# AC7840x register map
Vendor: AutoChips; Series: AC78; File version: 1.0
CPU: CM4 r0p1, little endian, MPU, FPU, VTOR, 4 interrupt priority bits
Registers are 32-bit, read-write, reset 0x0 unless marked. A register's access mark holds for its fields unless they carry their own. Offsets are from the block's base; [hi:lo] are bit positions; {n}, {i} and the like mark numbered series; 'fields as' and 'values as' point back to an identical list.

## GPIOA — General Purpose Input/Output
Base 0x40085000
Same registers: GPIOB 0x40085040, GPIOC 0x40085080, GPIOD 0x400850C0, GPIOE 0x40085100
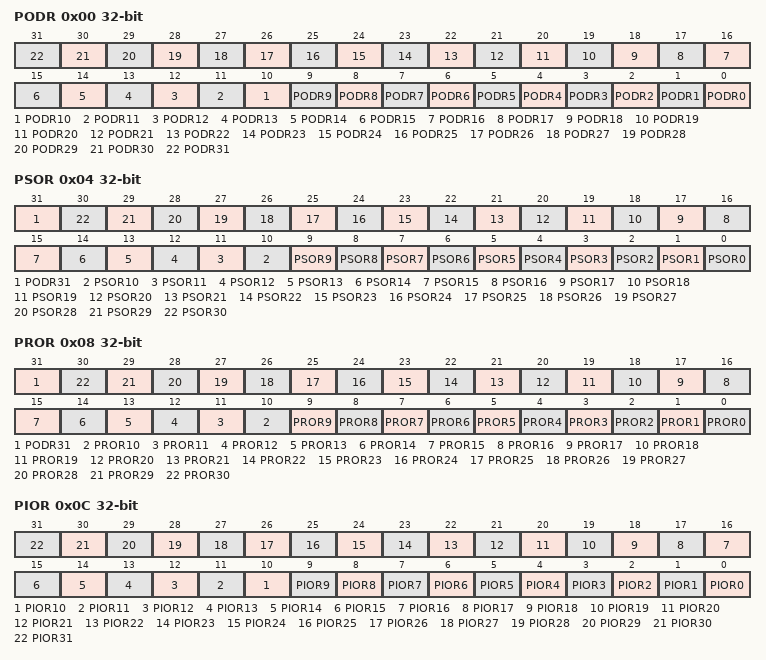
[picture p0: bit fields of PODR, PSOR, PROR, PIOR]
0x00 PODR — PORT Output Data Register
  [n] PODR{n} (n=0..31) — Port output data, bit {n}
0x04 PSOR — PORT Set Output Register
  [31] PODR31 — Port Set Output data, bit 31
  [n] PSOR{n} (n=0..30) — Port Set Output data, bit {n}
0x08 PROR — PORT Reset Output Register
  [31] PODR31 — Port Reset Output data, bit 31
  [n] PROR{n} (n=0..30) — Port Reset Output data, bit {n}
0x0C PIOR — PORT Invert Output Register
  [n] PIOR{n} (n=0..31) — Port Invert Output data, bit {n}
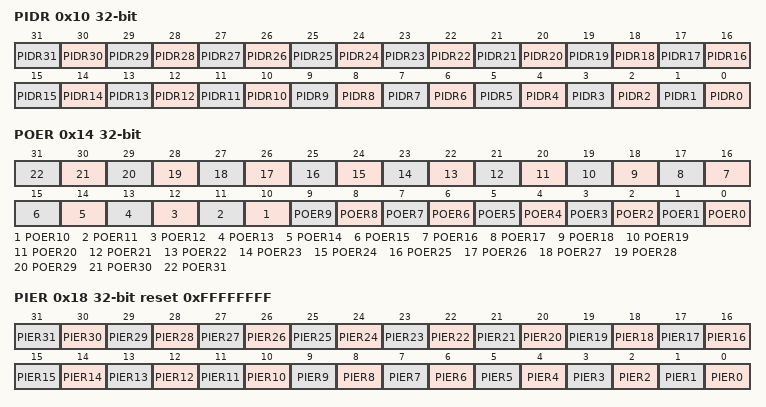
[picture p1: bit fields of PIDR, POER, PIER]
0x10 PIDR — PORT Input Data Register
  [n] PIDR{n} (n=0..31) — Port Input data, bit {n}
0x14 POER — PORT Output Enable Register
  [n] POER{n} (n=0..31) — Port Output Enable, bit {n}
0x18 PIER reset 0xFFFFFFFF — PORT Input Enable Register
  [n] PIER{n} (n=0..31) — Port Input Enable, bit {n}

## ANA — Analog Control Registers
Base 0x40008800
0x50 ACMPDAC_CFG reset 0x1000000 — ACMPDAC Configuration Register
  [16] RG_MCU_ACMPDAC_LP_EN — LP mode
    1=enable; 0=disable
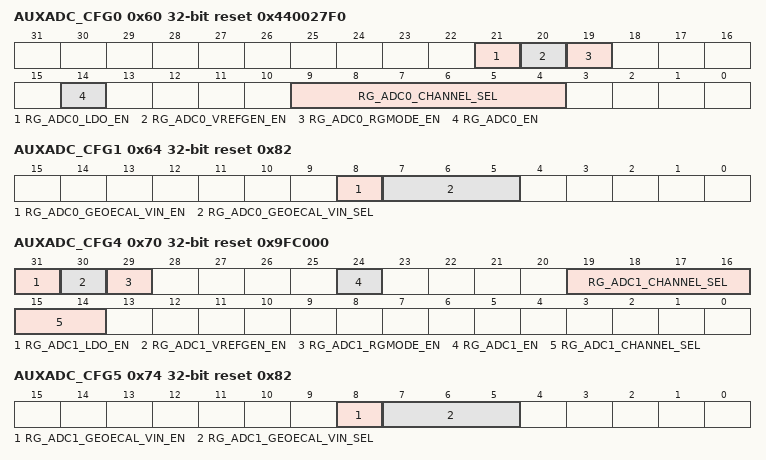
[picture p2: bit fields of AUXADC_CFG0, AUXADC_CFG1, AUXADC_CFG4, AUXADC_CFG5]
0x60 AUXADC_CFG0 reset 0x440027F0 — AUXADC Configuration Register0
  [21] RG_ADC0_LDO_EN — ADC0 LDO enable
    0=disable; 1=enable
  [20] RG_ADC0_VREFGEN_EN — ADC0 VREFGEN enable
    0=disable; 1=enable
  [19] RG_ADC0_RGMODE_EN — Registor debug mode enable
    0=normal mode, enable and channel_sel are controled by DA signal; 1=debug mode, enable and channel_sel are controled by RG signal
  [14] RG_ADC0_EN — ADC Enable
    0=disable; 1=enable
  [9:4] RG_ADC0_CHANNEL_SEL — adc input select
0x64 AUXADC_CFG1 reset 0x82 — AUXADC Configuration Register1
  [8] RG_ADC0_GEOECAL_VIN_EN — GEOE calibration enable
    0=disable; 1=enable
  [7:5] RG_ADC0_GEOECAL_VIN_SEL — GEOE calibration input voltage select
    0=Floating; 1=4*AVDD/16; 2=5*AVDD/16; 3=6*AVDD/16; 4=8*AVDD/16; 5=10*AVDD/16; 6=11*AVDD/16; 7=12*AVDD/16
0x70 AUXADC_CFG4 reset 0x9FC000 — AUXADC Configuration Register4
  [31] RG_ADC1_LDO_EN — ADC1 LDO enable
    0=disable; 1=enable
  [30] RG_ADC1_VREFGEN_EN — ADC1 VREFGEN enable
    0=disable; 1=enable
  [29] RG_ADC1_RGMODE_EN — Registor debug mode enable
    values as AUXADC_CFG0.RG_ADC0_RGMODE_EN
  [24] RG_ADC1_EN — ADC1 Enable
    0=disable; 1=enable
  [19:14] RG_ADC1_CHANNEL_SEL — adc input select
0x74 AUXADC_CFG5 reset 0x82 — AUXADC Configuration Register5
  [8] RG_ADC1_GEOECAL_VIN_EN — GEOE calibration enable
    0=disable; 1=enable
  [7:5] RG_ADC1_GEOECAL_VIN_SEL — GEOE calibration input voltage select
    values as AUXADC_CFG1.RG_ADC0_GEOECAL_VIN_SEL
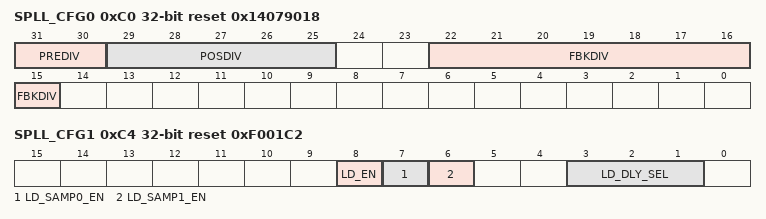
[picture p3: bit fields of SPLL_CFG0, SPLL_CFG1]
0xC0 SPLL_CFG0 reset 0x14079018 — System PLL Config 0
  [31:30] PREDIV — PLL Pre-Divider
    0=Fref=Fin/1; 1=Fref=Fin/2; 2=Fref=Fin/4; 3=Fref=Fin/4
  [29:25] POSDIV — PLL Post-divider Ratio
    0=NONE; 1=VCO/2; 2=VCO/4; 3=VCO/6; 4=VCO/8; 5=VCO/10; 6=VCO/12; 7=VCO/14; 8=VCO/16; 9=VCO/18; 10=VCO/20; 11=VCO/22; 12=VCO/24; 13=VCO/26; 14=VCO/28; 15=VCO/30; 16=VCO/32; 17=VCO/34; 18=VCO/36; 19=VCO/38; 20=VCO/40; 21=VCO/42; 22=VCO/44; 23=VCO/46; 24=VCO/48; 25=VCO/50; 26=VCO/52; 27=VCO/54; 28=VCO/56; 29=VCO/58; 30=VCO/60; 31=VCO/62
  [22:15] FBKDIV — PLL Feedback-Divider
0xC4 SPLL_CFG1 reset 0xF001C2 — System PLL Config 1
  [8] LD_EN — PLL Lock Detect Enable
    0=DISABLE; 1=ENABLE
  [7] LD_SAMP0_EN — PLL Lock Detect Sample 0 Enable
    0=DISABLE; 1=ENABLE
  [6] LD_SAMP1_EN — PLL Lock Detect Sample 1 Enable
    0=DISABLE; 1=ENABLE
  [3:1] LD_DLY_SEL — PLL Lock Detect Comparision Delay Select
    0=300ps; 1=600ps; 2=900ps; 3=1200ps; 4=2200ps; 5=3200ps; 6=4200ps; 7=5200ps

## ACMP0 — Analog comparator
Base 0x40005000
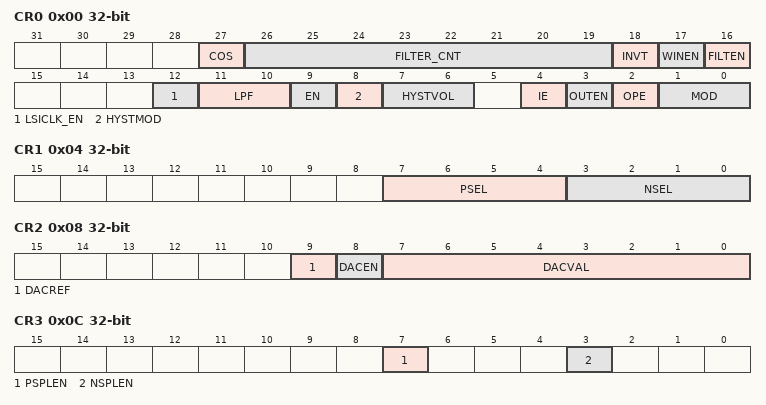
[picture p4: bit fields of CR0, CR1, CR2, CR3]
0x00 CR0 — ACMP Configuration Register 0
  [27] COS — ACMP output select
    0=set CMPO to equal COUT(filtered); 1=set CMPO to equal COUTA(unfiltered)
  [26:19] FILTER_CNT — Filter Count
  [18] INVT — Comparator invert
    0=Does not invert the comparator output; 1=Inverts the comparator output
  [17] WINEN — Windown mode Enable
    0=Windown mode is disabled; 1=Windown mode is enabled
  [16] FILTEN — Digital Filter Enable
    0=Digital Filter is disabled; 1=Digital Filter is enabled
  [12] LSICLK_EN — ACMP function clock select
    0=BUS_CLK without gate control; 1=LSI 128K clock
  [11:10] LPF — Low pass filter
    0=500KHz; 1=1MHz; 2=2MHz; 3=bypass
  [9] EN — Analog Comparator Enable
    0=ACMP is disabled; 1=ACMP is enabled
  [8] HYSTMOD — Hysteresis mode
    0=Falling edge; 1=Both edge
  [7:6] HYSTVOL — Hysteresis voltage
    0=0mV; 1=10mV; 2=20mV; 3=40mV
  [4] IE — Interrupt Enable
    0=Disable the interrupt; 1=Enable the interrupt
  [3] OUTEN — ACMP Output Enable
    0=Disable ACMP OUTPUT; 1=Enable ACMP OUTPUT
  [2] OPE — ACMP hall output Enable
    0=ACMP hall output Disabled; 1=ACMP hall output enabled
  [1:0] MOD — ACMP sensitivity modes of the interrupt trigger
    0=ACMP interrupt on output falling edge; 1=ACMP interrupt on output rising edge; 2=ACMP interrupt on output falling edge; 3=ACMP interrupt on output falling or rising edge
0x04 CR1 — ACMP Configuration Register 1
  [7:4] PSEL — ACMP Positive Input Select
    {v}=External input {v} (v=0..7); 8=DAC output
  [3:0] NSEL — ACMP Negative Input Select
    {v}=External input {v} (v=0..7); 8=DAC output
0x08 CR2 — ACMP configuration register 2
  [9] DACREF — ACMP DAC reference select
    0=DAC selects bandgap as reference; 1=DAC selects Vdd as reference
  [8] DACEN — DAC Enable
    0=The DAC is disabled; 1=The DAC is enabled
  [7:0] DACVAL — DAC Output Value
0x0C CR3 — ACMP configuration register 3
  [7] PSPLEN — ACMP positive input polling mode enable
    0=ACMP positive input polling mode disabled; 1=ACMP positive input polling mode enabled
  [3] NSPLEN — ACMP negative input polling mode enable
    0=ACMP negative input polling mode disabled; 1=ACMP negative input polling mode enabled
0x10 CR4 — ACMP configuration register 4
  [8:0] PLSEQ — ACMP polling channel sequence set
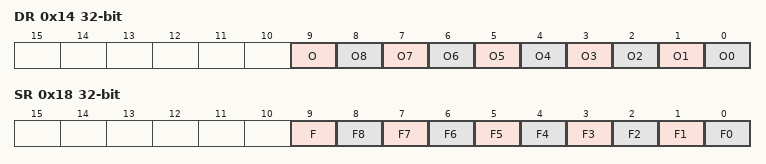
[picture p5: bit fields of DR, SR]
0x14 DR ro — ACMP data output register 0
  [9] O — ACMP general mode output
  [n] O{n} (n=0..8) — ACMP polling mode channel {n} output
0x18 SR — ACMP status register 0
  [9] F — ACMP general mode interrupt flag
  [n] F{n} (n=0..8) — ACMP polling mode channel {n} interrupt flag
0x1C FD — ACMP polling frequency divider register
  [1:0] PLFD — ACMP polling mode frequency divider
    0=source_clk/256; 1=source_clk/101; 2=source_clk/71; 3=source_clk/51
0x20 OPA — ACMP hall output A register
  [3:0] OPSEL — ACMP Hall output
    {v}=polling channel {v} (v=0..7); 8=polling DAC
0x24 OPB — ACMP hall output B register
  fields as OPA
0x28 OPC — ACMP hall output C register
  fields as OPA
0x48 CLK — ACMP clock register
  [2:0] PSC — Input clock prescaler
    {v}=Divide by {v+1} (v=0..7)
